# comp_e register map
Vendor: Texas Instruments
Peripheral module from a debugger description file (folder MSP432).
Registers are 16-bit, read-write, no defined reset value unless marked. A register's access mark holds for its fields unless they carry their own. Offsets are as the file gives them; lines under a group give offsets from that group; [hi:lo] are bit positions; {n}, {i} and the like mark numbered series; 'fields as' and 'values as' point back to an identical list; <NAME> marks a mode.

## COMP_E
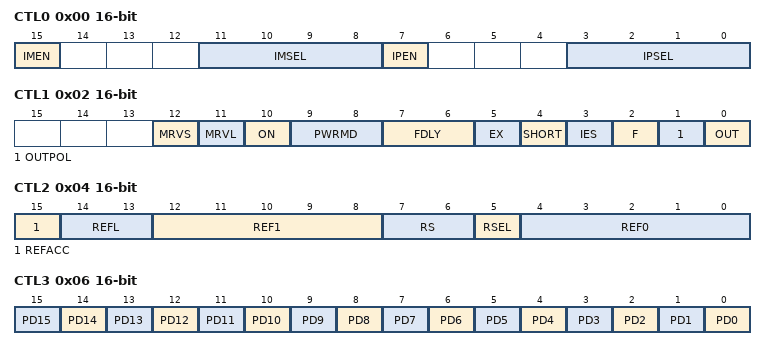
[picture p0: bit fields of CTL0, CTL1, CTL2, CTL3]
0x00 CTL0 — Comparator Control Register 0
  [15] IMEN — Channel input enable for the - terminal of the comparator.
    0=IMEN__0 (Selected analog input channel for V- terminal is disabled); 1=IMEN__1 (Selected analog input channel for V- terminal is enabled)
  [11:8] IMSEL — Channel input selected for the - terminal of the comparator if
    {v}=IMSEL__{v} (Channel {v} selected) (v=0..9); {v}=IMSEL__{v+6} (Channel {v} selected) (v=10..15)
  [7] IPEN — Channel input enable for the V+ terminal of the comparator.
    0=IPEN__0 (Selected analog input channel for V+ terminal is disabled); 1=IPEN__1 (Selected analog input channel for V+ terminal is enabled)
  [3:0] IPSEL — Channel input selected for the V+ terminal of the comparator if
    {v}=IPSEL__{v} (Channel {v} selected) (v=0..9); {v}=IPSEL__{v+6} (Channel {v} selected) (v=10..15)
0x02 CTL1 — Comparator Control Register 1
  [12] MRVS — This bit defines if the comparator output selects between VREF0
    0=MRVS__0 (Comparator output state selects between VREF0 or VREF1); 1=MRVS__1 (CEMRVL selects between VREF0 or VREF1)
  [11] MRVL — This bit is valid of CEMRVS is set to 1.
    0=MRVL__0 (VREF0 is selected if CERS = 00, 01, or 10); 1=MRVL__1 (VREF1 is selected if CERS = 00, 01, or 10)
  [10] ON
    0=ON__0 (Off); 1=ON__1
  [9:8] PWRMD — Power Mode
    0=PWRMD__0 (High-speed mode); 1=PWRMD__1 (Normal mode); 2=PWRMD__2 (Ultra-low power mode)
  [7:6] FDLY — Filter delay
    0=FDLY__0 (Typical filter delay of TBD (450) ns); 1=FDLY__1 (Typical filter delay of TBD (900) ns); 2=FDLY__2 (Typical filter delay of TBD (1800) ns); 3=FDLY__3 (Typical filter delay of TBD (3600) ns)
  [5] EX — Exchange
  [4] SHORT — Input short. This bit shorts the + and – input terminals.
    0=SHORT__0 (Inputs not shorted); 1=SHORT__1 (Inputs shorted)
  [3] IES — Interrupt edge select for CEIIFG and CEIFG.
    0=IES__0 (Rising edge for CEIFG, falling edge for CEIIFG); 1=IES__1 (Falling edge for CEIFG, rising edge for CEIIFG)
  [2] F — Output filter. Available if CEPWRMD = 00, 01.
    0=F__0 (Comparator output is not filtered); 1=F__1 (Comparator output is filtered)
  [1] OUTPOL — Output polarity. This bit defines the CEOUT polarity.
    0=OUTPOL__0 (Noninverted); 1=OUTPOL__1 (Inverted)
  [0] OUT — Output value
0x04 CTL2 — Comparator Control Register 2
  [15] REFACC — Reference accuracy
    0=REFACC__0 (Static mode); 1=REFACC__1 (Clocked (low power, low accuracy) mode)
  [14:13] REFL — Reference voltage level
    0=REFL__0 (Reference amplifier is disabled); 1=REFL__1 (1.2 V is selected as shared reference voltage input); 2=REFL__2 (2.0 V is selected as shared reference voltage input); 3=REFL__3 (2.5 V is selected as shared reference voltage input)
  [12:8] REF1 — Reference resistor tap 1
  [7:6] RS — Reference source
    0=RS__0 (No current is drawn by the reference circuitry); 1=RS__1 (VCC applied to the resistor ladder); 2=RS__2 (Shared reference voltage applied to the resistor ladder); 3=RS__3 (Shared reference voltage supplied to V(CREF))
  [5] RSEL — Reference select
    0=RSEL__0 (When CEEX = 0, VREF is applied to the V+ terminal; When CEEX =); 1=RSEL__1 (When CEEX = 0, VREF is applied to the V- terminal; When CEEX =)
  [4:0] REF0 — Reference resistor tap 0
0x06 CTL3 — Comparator Control Register 3
  [n] PD{n} (n=0..15) — Port disable
    0=PD{n}__0 (The input buffer is enabled); 1=PD{n}__1 (The input buffer is disabled)
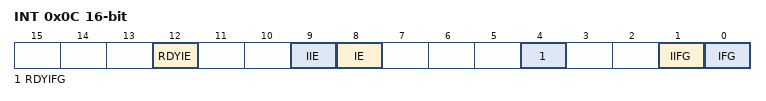
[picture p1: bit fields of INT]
0x0C INT — Comparator Interrupt Control Register
  [12] RDYIE — Comparator ready interrupt enable.
    0=RDYIE__0 (Interrupt disabled); 1=RDYIE__1 (Interrupt enabled)
  [9] IIE — Comparator output interrupt enable inverted polarity.
    0=IIE__0 (Interrupt disabled); 1=IIE__1 (Interrupt enabled)
  [8] IE — Comparator output interrupt enable.
    0=IE__0 (Interrupt disabled); 1=IE__1 (Interrupt enabled)
  [4] RDYIFG — Comparator ready interrupt flag
    0=RDYIFG__0 (No interrupt pending); 1=RDYIFG__1 (Interrupt pending)
  [1] IIFG — Comparator output inverted interrupt flag
    0=IIFG__0 (No interrupt pending); 1=IIFG__1 (Interrupt pending)
  [0] IFG — Comparator output interrupt flag
    0=IFG__0 (No interrupt pending); 1=IFG__1 (Interrupt pending)
0x0E IV — Comparator Interrupt Vector Word Register
  [15:0] IV — Comparator interrupt vector word register
    0=IV__0 (No interrupt pending); 2=IV__2 (Interrupt Source: CEOUT interrupt; Interrupt Flag: CEIFG; Inter); 4=IV__4 (Interrupt Source: CEOUT interrupt inverted polarity; Interrupt); 10=IV__16 (Interrupt Source: Comparator ready interrupt; Interrupt Flag: C)
